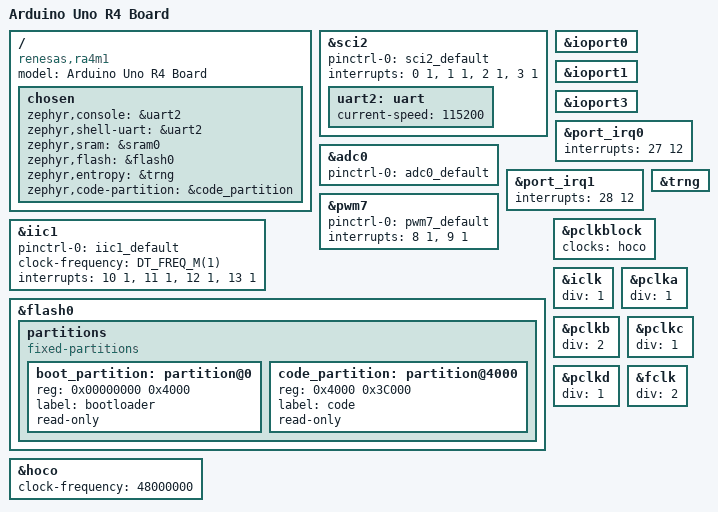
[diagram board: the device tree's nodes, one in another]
/*
 * Copyright (c) 2023 TOKITA Hiroshi <tokita.hiroshi@fujitsu.com>
 *
 * SPDX-License-Identifier: Apache-2.0
 */

/dts-v1/;

#include <renesas/ra/ra4/r7fa4m1ab3cfm.dtsi>
#include "arduino_uno_r4-pinctrl.dtsi"
#include <zephyr/dt-bindings/gpio/gpio.h>
#include <zephyr/dt-bindings/adc/adc.h>

/ {
	compatible = "renesas,ra4m1", "renesas,ra";
	model = "Arduino Uno R4 Board";

	chosen {
		zephyr,console = &uart2;
		zephyr,shell-uart = &uart2;
		zephyr,sram = &sram0;
		zephyr,flash = &flash0;
		zephyr,entropy = &trng;
		zephyr,code-partition = &code_partition;
	};
};

&sci2 {
	pinctrl-0 = <&sci2_default>;
	pinctrl-names = "default";
	interrupts = <0 1>, <1 1>, <2 1>, <3 1>;
	interrupt-names = "rxi", "txi", "tei", "eri";
	status = "okay";

	uart2: uart {
		current-speed = <115200>;
		status = "okay";
	};
};

&ioport0 {
	status = "okay";
};

&ioport1 {
	status = "okay";
};

&ioport3 {
	status = "okay";
};

&adc0 {
	pinctrl-0 = <&adc0_default>;
	pinctrl-names = "default";
	status = "okay";
};

&port_irq0 {
	interrupts = <27 12>;
	status = "okay";
};

&port_irq1 {
	interrupts = <28 12>;
	status = "okay";
};

&trng {
	status = "okay";
};

&pwm7 {
	pinctrl-0 = <&pwm7_default>;
	pinctrl-names = "default";
	interrupts = <8 1>, <9 1>;
	interrupt-names = "gtioca", "overflow";
	status = "okay";
};

&iic1 {
	pinctrl-0 = <&iic1_default>;
	pinctrl-names = "default";
	#address-cells = <1>;
	#size-cells = <0>;
	clock-frequency = <DT_FREQ_M(1)>;
	interrupts = <10 1>, <11 1>, <12 1>, <13 1>;
	interrupt-names = "rxi", "txi", "tei", "eri";
	status = "okay";
};

&flash0 {
	partitions {
		compatible = "fixed-partitions";
		#address-cells = <1>;
		#size-cells = <1>;

		boot_partition: partition@0 {
			reg = <0x00000000 0x4000>;
			label = "bootloader";
			read-only;
		};

		code_partition: partition@4000 {
			reg = <0x4000 0x3C000>;
			label = "code";
			read-only;
		};
	};
};

&hoco {
	clock-frequency = <48000000>;
	status = "okay";
};

&pclkblock {
	clocks = <&hoco>;
};

&iclk {
	div = <1>;
};

&pclka {
	div = <1>;
};

&pclkb {
	div = <2>;
};

&pclkc {
	div = <1>;
};

&pclkd {
	div = <1>;
};

&fclk {
	div = <2>;
};
